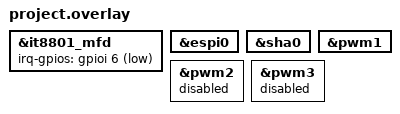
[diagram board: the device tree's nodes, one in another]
/* Copyright 2025 The ChromiumOS Authors
 * Use of this source code is governed by a BSD-style license that can be
 * found in the LICENSE file.
 */

/* ocelot program common DTS includes */

#include <cros/integrated_fwid.dtsi>

/* ocelotrvp-ite project DTS includes */

#include "binman.dtsi"
#include "board.dtsi"
#include "../ite_hibernate.dtsi"
#include <ite/it8801-common-cfg.dtsi>

&it8801_mfd {
	irq-gpios = <&gpioi 6 GPIO_ACTIVE_LOW>;
};

&espi0 {
	status = "okay";
};

&sha0 {
	status = "okay";
};

&pwm1 {
	status = "okay";
};
&pwm2 {
	status = "disabled";
};
&pwm3 {
	status = "disabled";
};
